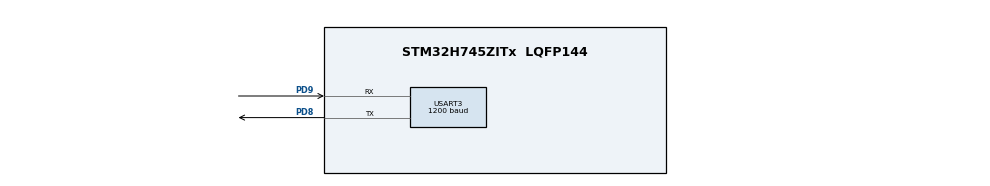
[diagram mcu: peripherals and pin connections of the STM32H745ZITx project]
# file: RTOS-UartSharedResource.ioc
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CortexM4.IPs=BDMA,CORTEX_M4\:I,DEBUG,DMA,FATFS_M4\:I,FREERTOS_M4\:I,GPIO,IWDG2\:I,MDMA,NVIC2\:I,OPENAMP_M4\:I,PDM2PCM_M4\:I,PWR,RCC,RESMGR_UTILITY,SYS_M4\:I,USB_DEVICE_M4\:I,USB_HOST_M4\:I,VREFBUF,WWDG2\:I
CortexM7.IPs=BDMA\:I,CORTEX_M7\:I,DEBUG\:I,DMA\:I,FATFS_M7\:I,FREERTOS_M7\:I,GPIO\:I,IWDG1\:I,MDMA\:I,NVIC1\:I,OPENAMP_M7\:I,PDM2PCM_M7\:I,PWR\:I,RCC\:I,RESMGR_UTILITY\:I,SYS\:I,USB_DEVICE_M7\:I,USB_HOST_M7\:I,VREFBUF\:I,WWDG1\:I,USART3\:I,TIM6\:I
FREERTOS_M7.BinarySemaphores01=Semaphore1,Dynamic,NULL
FREERTOS_M7.Mutexes01=Mutex1,Dynamic,NULL
FREERTOS_M7.Tasks01=Task1,8,128,Task1Function,Default,NULL,Dynamic,NULL,NULL;Task2,9,128,Task2Function,Default,NULL,Dynamic,NULL,NULL;Task3,10,128,Task3Function,Default,NULL,Dynamic,NULL,NULL;Task4,11,128,Task4Function,Default,NULL,Dynamic,NULL,NULL
FREERTOS_M7.configUSE_NEWLIB_REENTRANT=1
Mcu.Family=STM32H7
Mcu.Name=STM32H745ZITx
Mcu.Package=LQFP144
NVIC1.PriorityGroup=NVIC_PRIORITYGROUP_4
NVIC1.TIM6_DAC_IRQn=true\:15\:0\:false\:false\:true\:false\:false\:true\:true
NVIC1.TimeBase=TIM6_DAC_IRQn
NVIC1.TimeBaseIP=TIM6
NVIC1.USART3_IRQn=true\:5\:0\:false\:false\:true\:true\:true\:true\:true
NVIC2.PriorityGroup=NVIC_PRIORITYGROUP_4
PD8.Mode=Asynchronous
PD8.PinAttribute=CortexM7
PD8.Signal=USART3_TX
PD9.Mode=Asynchronous
PD9.PinAttribute=CortexM7
PD9.Signal=USART3_RX
ProjectManager.HeapSize=M4-0x200,M7-0x200
ProjectManager.StackSize=M4-0x400,M7-0x400
ProjectManager.TargetToolchain=STM32CubeIDE
RCC.ADCFreq_Value=129000000
RCC.APB1Freq_Value=32000000
RCC.APB2Freq_Value=64000000
RCC.APB3Freq_Value=64000000
RCC.APB4Freq_Value=64000000
RCC.CortexFreq_Value=64000000
RCC.D2PPRE1=RCC_APB1_DIV2
RCC.HCLKFreq_Value=64000000
RCC.SYSCLKFreq_VALUE=64000000
RCC.USBFreq_Value=129000000
SYS.userName=SYS_M7
USART3.BaudRate=1200
USART3.VirtualMode-Asynchronous=VM_ASYNC
VP_FREERTOS_M7_VS_CMSIS_V2.Mode=CMSIS_V2
VP_SYS_VS_tim6.Mode=TIM6
board=custom

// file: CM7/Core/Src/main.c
/* USER CODE BEGIN Header */
/**
 ******************************************************************************
 * @file           : main.c
 * @brief          : Main program body
 ******************************************************************************
 * @attention
 *
 * Copyright (c) 2022 STMicroelectronics.
 * All rights reserved.
 *
 * This software is licensed under terms that can be found in the LICENSE file
 * in the root directory of this software component.
 * If no LICENSE file comes with this software, it is provided AS-IS.
 *
 ******************************************************************************
 */
/* USER CODE END Header */
#include "main.h"
#include "cmsis_os.h"

/* USER CODE BEGIN PD */

#ifndef HSEM_ID_0
#define HSEM_ID_0 (0U) /* HW semaphore 0*/
#endif

#define TX_BUFFER_SIZE 		20
#define TX_MAX_DELAY		0xffffffff
#define PERIODICITY_TASK1 	4
#define PERIODICITY_TASK2 	3
#define PERIODICITY_TASK3 	2
#define PERIODICITY_TASK4 	1

#define USE_SEMAPHORE		0
#define USE_MUTEX			1
/* USER CODE END PD */

UART_HandleTypeDef huart3;

/* Definitions for Task1 */
osThreadId_t Task1Handle;
const osThreadAttr_t Task1_attributes = {
		.name = "Task1",
		.stack_size = 128 * 4,
		.priority = (osPriority_t) osPriorityLow,
};
/* Definitions for Task2 */
osThreadId_t Task2Handle;
const osThreadAttr_t Task2_attributes = {
		.name = "Task2",
		.stack_size = 128 * 4,
		.priority = (osPriority_t) osPriorityLow1,
};
/* Definitions for Task3 */
osThreadId_t Task3Handle;
const osThreadAttr_t Task3_attributes = {
		.name = "Task3",
		.stack_size = 128 * 4,
		.priority = (osPriority_t) osPriorityLow2,
};
/* Definitions for Task4 */
osThreadId_t Task4Handle;
const osThreadAttr_t Task4_attributes = {
		.name = "Task4",
		.stack_size = 128 * 4,
		.priority = (osPriority_t) osPriorityLow3,
};
/* Definitions for Mutex1 */
osMutexId_t Mutex1Handle;
const osMutexAttr_t Mutex1_attributes = {
		.name = "Mutex1"
};
/* Definitions for Semaphore1 */
osSemaphoreId_t Semaphore1Handle;
const osSemaphoreAttr_t Semaphore1_attributes = {
		.name = "Semaphore1"
};
/* USER CODE BEGIN PV */
char* RTOS_TxBufferu_ac = NULL;
char RTOS_TaskMsg1_ac[TX_BUFFER_SIZE] = "Hello from task 1  \n";
char RTOS_TaskMsg2_ac[TX_BUFFER_SIZE] = "Hello from task 2  \n";
char RTOS_TaskMsg3_ac[TX_BUFFER_SIZE] = "Hello from task 3  \n";
char RTOS_TaskMsg4_ac[TX_BUFFER_SIZE] = "Hello from task 4  \n";
/* USER CODE END PV */

void SystemClock_Config(void);
static void MX_GPIO_Init(void);
static void MX_USART3_UART_Init(void);
void Task1Function(void *argument);
void Task2Function(void *argument);
void Task3Function(void *argument);
void Task4Function(void *argument);

/* USER CODE BEGIN PFP */
HAL_StatusTypeDef FEKI_UART_Transmit(UART_HandleTypeDef *huart, const uint8_t *pData, uint16_t Size, uint32_t Timeout);
/* USER CODE END PFP */

int main(void)
{
	/* USER CODE BEGIN Boot_Mode_Sequence_0 */
	/* USER CODE END Boot_Mode_Sequence_0 */

	/* USER CODE BEGIN Boot_Mode_Sequence_1 */
	/* USER CODE END Boot_Mode_Sequence_1 */
	/* MCU Configuration--------------------------------------------------------*/

	/* Reset of all peripherals, Initializes the Flash interface and the Systick. */
	HAL_Init();

	/* Configure the system clock */
	SystemClock_Config();
	/* USER CODE BEGIN Boot_Mode_Sequence_2 */
	/* USER CODE END Boot_Mode_Sequence_2 */

	/* Initialize all configured peripherals */
	MX_GPIO_Init();
	MX_USART3_UART_Init();
	/* USER CODE BEGIN 2 */
	//  FEKI_UART_Transmit(&huart3, (uint8_t*)RTOS_TaskMsg4_ac, TX_BUFFER_SIZE, TX_MAX_DELAY);
	//  while(1);
	/* USER CODE END 2 */

	/* Init scheduler */
	osKernelInitialize();
	/* Create the mutex(es) */
	/* creation of Mutex1 */
	Mutex1Handle = osMutexNew(&Mutex1_attributes);

	/* Create the semaphores(s) */
	/* creation of Semaphore1 */
	Semaphore1Handle = osSemaphoreNew(1, 1, &Semaphore1_attributes);

	/* Create the thread(s) */
	/* creation of Task1 */
	Task1Handle = osThreadNew(Task1Function, NULL, &Task1_attributes);

	/* creation of Task2 */
	Task2Handle = osThreadNew(Task2Function, NULL, &Task2_attributes);

	/* creation of Task3 */
	Task3Handle = osThreadNew(Task3Function, NULL, &Task3_attributes);

	/* creation of Task4 */
	Task4Handle = osThreadNew(Task4Function, NULL, &Task4_attributes);

	/* Start scheduler */
	osKernelStart();

	/* We should never get here as control is now taken by the scheduler */
	/* Infinite loop */
	while (1)
	{

	}
}

void SystemClock_Config(void)
{
	RCC_OscInitTypeDef RCC_OscInitStruct = {0};
	RCC_ClkInitTypeDef RCC_ClkInitStruct = {0};

	/** Supply configuration update enable
	 */
	HAL_PWREx_ConfigSupply(PWR_DIRECT_SMPS_SUPPLY);

	/** Configure the main internal regulator output voltage
	 */
	__HAL_PWR_VOLTAGESCALING_CONFIG(PWR_REGULATOR_VOLTAGE_SCALE3);

	while(!__HAL_PWR_GET_FLAG(PWR_FLAG_VOSRDY)) {}

	/** Initializes the RCC Oscillators according to the specified parameters
	 * in the RCC_OscInitTypeDef structure.
	 */
	RCC_OscInitStruct.OscillatorType = RCC_OSCILLATORTYPE_HSI;
	RCC_OscInitStruct.HSIState = RCC_HSI_DIV1;
	RCC_OscInitStruct.HSICalibrationValue = RCC_HSICALIBRATION_DEFAULT;
	RCC_OscInitStruct.PLL.PLLState = RCC_PLL_NONE;
	if (HAL_RCC_OscConfig(&RCC_OscInitStruct) != HAL_OK)
	{
		Error_Handler();
	}

	/** Initializes the CPU, AHB and APB buses clocks
	 */
	RCC_ClkInitStruct.ClockType = RCC_CLOCKTYPE_HCLK|RCC_CLOCKTYPE_SYSCLK
			|RCC_CLOCKTYPE_PCLK1|RCC_CLOCKTYPE_PCLK2
			|RCC_CLOCKTYPE_D3PCLK1|RCC_CLOCKTYPE_D1PCLK1;
	RCC_ClkInitStruct.SYSCLKSource = RCC_SYSCLKSOURCE_HSI;
	RCC_ClkInitStruct.SYSCLKDivider = RCC_SYSCLK_DIV1;
	RCC_ClkInitStruct.AHBCLKDivider = RCC_HCLK_DIV1;
	RCC_ClkInitStruct.APB3CLKDivider = RCC_APB3_DIV1;
	RCC_ClkInitStruct.APB1CLKDivider = RCC_APB1_DIV2;
	RCC_ClkInitStruct.APB2CLKDivider = RCC_APB2_DIV1;
	RCC_ClkInitStruct.APB4CLKDivider = RCC_APB4_DIV1;

	if (HAL_RCC_ClockConfig(&RCC_ClkInitStruct, FLASH_LATENCY_1) != HAL_OK)
	{
		Error_Handler();
	}
}

static void MX_USART3_UART_Init(void)
{

	huart3.Instance = USART3;
	huart3.Init.BaudRate = 1200;
	huart3.Init.WordLength = UART_WORDLENGTH_8B;
	huart3.Init.StopBits = UART_STOPBITS_1;
	huart3.Init.Parity = UART_PARITY_NONE;
	huart3.Init.Mode = UART_MODE_TX_RX;
	huart3.Init.HwFlowCtl = UART_HWCONTROL_NONE;
	huart3.Init.OverSampling = UART_OVERSAMPLING_16;
	huart3.Init.OneBitSampling = UART_ONE_BIT_SAMPLE_DISABLE;
	huart3.Init.ClockPrescaler = UART_PRESCALER_DIV1;
	huart3.AdvancedInit.AdvFeatureInit = UART_ADVFEATURE_NO_INIT;
	if (HAL_UART_Init(&huart3) != HAL_OK)
	{
		Error_Handler();
	}
	if (HAL_UARTEx_SetTxFifoThreshold(&huart3, UART_TXFIFO_THRESHOLD_1_8) != HAL_OK)
	{
		Error_Handler();
	}
	if (HAL_UARTEx_SetRxFifoThreshold(&huart3, UART_RXFIFO_THRESHOLD_1_8) != HAL_OK)
	{
		Error_Handler();
	}
	if (HAL_UARTEx_DisableFifoMode(&huart3) != HAL_OK)
	{
		Error_Handler();
	}

}

static void MX_GPIO_Init(void)
{

	/* GPIO Ports Clock Enable */
	__HAL_RCC_GPIOD_CLK_ENABLE();

}

/* USER CODE BEGIN 4 */
HAL_StatusTypeDef FEKI_UART_Transmit(UART_HandleTypeDef *huart, const uint8_t *pData, uint16_t Size, uint32_t Timeout)
{
	const uint8_t  *pdata8bits;
	const uint16_t *pdata16bits;
	uint32_t tickstart;

	/* Check that a Tx process is not already ongoing */

	if ((pData == NULL) || (Size == 0U))
	{
		return  HAL_ERROR;
	}

	//__HAL_LOCK(huart);

	huart->ErrorCode = HAL_UART_ERROR_NONE;
	huart->gState = HAL_UART_STATE_BUSY_TX;

	/* Init tickstart for timeout management */
	tickstart = HAL_GetTick();

	huart->TxXferSize  = Size;
	huart->TxXferCount = Size;

	/* In case of 9bits/No Parity transfer, pData needs to be handled as a uint16_t pointer */
	if ((huart->Init.WordLength == UART_WORDLENGTH_9B) && (huart->Init.Parity == UART_PARITY_NONE))
	{
		pdata8bits  = NULL;
		pdata16bits = (const uint16_t *) pData;
	}
	else
	{
		pdata8bits  = pData;
		pdata16bits = NULL;
	}

	//__HAL_UNLOCK(huart);

	while (huart->TxXferCount > 0U)
	{
		if (UART_WaitOnFlagUntilTimeout(huart, UART_FLAG_TXE, RESET, tickstart, Timeout) != HAL_OK)
		{
			return HAL_TIMEOUT;
		}
		if (pdata8bits == NULL)
		{
			huart->Instance->TDR = (uint16_t)(*pdata16bits & 0x01FFU);
			pdata16bits++;
		}
		else
		{
			huart->Instance->TDR = (uint8_t)(*pdata8bits & 0xFFU);
			pdata8bits++;
		}
		huart->TxXferCount--;
	}

	//    if (UART_WaitOnFlagUntilTimeout(huart, UART_FLAG_TC, RESET, tickstart, Timeout) != HAL_OK)
	//    {
	//      return HAL_TIMEOUT;
	//    }

	/* At end of Tx process, restore huart->gState to Ready */
	//huart->gState = HAL_UART_STATE_READY;

	return HAL_OK;

}
/* USER CODE END 4 */

void Task1Function(void *argument)
{
	/* USER CODE BEGIN 5 */
	uint8_t occurence1 = 0;
	/* Infinite loop */
	for(;;)
	{
		osDelay(PERIODICITY_TASK1);
		occurence1 ++ ;
#if USE_SEMAPHORE
		if (osOK == osSemaphoreAcquire(Semaphore1Handle, portMAX_DELAY))
#endif
#if USE_MUTEX
			if (osOK == osMutexAcquire(Mutex1Handle, portMAX_DELAY))
#endif
			{
				RTOS_TaskMsg1_ac[18] = (char)(occurence1 + 48);
				FEKI_UART_Transmit(&huart3, (uint8_t*)RTOS_TaskMsg1_ac, TX_BUFFER_SIZE, TX_MAX_DELAY);
#if USE_SEMAPHORE
				osSemaphoreRelease(Semaphore1Handle);
#endif

#if USE_MUTEX
				osMutexRelease(Mutex1Handle);
#endif
			}
			else
			{
				/* do nothing */
			}
	}
	/* USER CODE END 5 */
}

void Task2Function(void *argument)
{
	/* USER CODE BEGIN Task2Function */
	uint8_t occurence2 = 0;
	/* Infinite loop */
	for(;;)
	{
		osDelay(PERIODICITY_TASK2);
		occurence2 ++ ;
#if USE_SEMAPHORE
		if (osOK == osSemaphoreAcquire(Semaphore1Handle, portMAX_DELAY))
#endif
#if USE_MUTEX
			if (osOK == osMutexAcquire(Mutex1Handle, portMAX_DELAY))
#endif
			{
				RTOS_TaskMsg2_ac[18] = (char)(occurence2 + 48);
				FEKI_UART_Transmit(&huart3, (uint8_t*)RTOS_TaskMsg2_ac, TX_BUFFER_SIZE, TX_MAX_DELAY);
#if USE_SEMAPHORE
				osSemaphoreRelease(Semaphore1Handle);
#endif

#if USE_MUTEX
				osMutexRelease(Mutex1Handle);
#endif
			}
			else
			{
				/* do nothing */
			}

	}
	/* USER CODE END Task2Function */
}

void Task3Function(void *argument)
{
	/* USER CODE BEGIN Task3Function */
	uint8_t occurence3 = 0;
	/* Infinite loop */
	for(;;)
	{
		osDelay(PERIODICITY_TASK3);
		occurence3 ++ ;
#if USE_SEMAPHORE
		if (osOK == osSemaphoreAcquire(Semaphore1Handle, portMAX_DELAY))
#endif
#if USE_MUTEX
			if (osOK == osMutexAcquire(Mutex1Handle, portMAX_DELAY))
#endif
			{
				RTOS_TaskMsg3_ac[18] = (char)(occurence3 + 48);
				FEKI_UART_Transmit(&huart3, (uint8_t*)RTOS_TaskMsg3_ac, TX_BUFFER_SIZE, TX_MAX_DELAY);
#if USE_SEMAPHORE
				osSemaphoreRelease(Semaphore1Handle);
#endif

#if USE_MUTEX
				osMutexRelease(Mutex1Handle);
#endif
			}
			else
			{
				/* do nothing */
			}

	}
	/* USER CODE END Task3Function */
}

void Task4Function(void *argument)
{
	/* USER CODE BEGIN Task4Function */
	uint8_t occurence4 = 0;
	/* Infinite loop */
	for(;;)
	{
		osDelay(PERIODICITY_TASK4);
		occurence4 ++ ;
#if USE_SEMAPHORE
		if (osOK == osSemaphoreAcquire(Semaphore1Handle, portMAX_DELAY))
#endif
#if USE_MUTEX
			if (osOK == osMutexAcquire(Mutex1Handle, portMAX_DELAY))
#endif
			{
				RTOS_TaskMsg4_ac[18] = (char)(occurence4 + 48);
				FEKI_UART_Transmit(&huart3, (uint8_t*)RTOS_TaskMsg4_ac, TX_BUFFER_SIZE, TX_MAX_DELAY);
#if USE_SEMAPHORE
				osSemaphoreRelease(Semaphore1Handle);
#endif

#if USE_MUTEX
				osMutexRelease(Mutex1Handle);
#endif
			}
			else
			{
				/* do nothing */
			}
	}
	/* USER CODE END Task4Function */
}

void HAL_TIM_PeriodElapsedCallback(TIM_HandleTypeDef *htim)
{
	if (htim->Instance == TIM6) {
		HAL_IncTick();
	}
}

void Error_Handler(void)
{
	__disable_irq();
	while (1)
	{
	}
}
